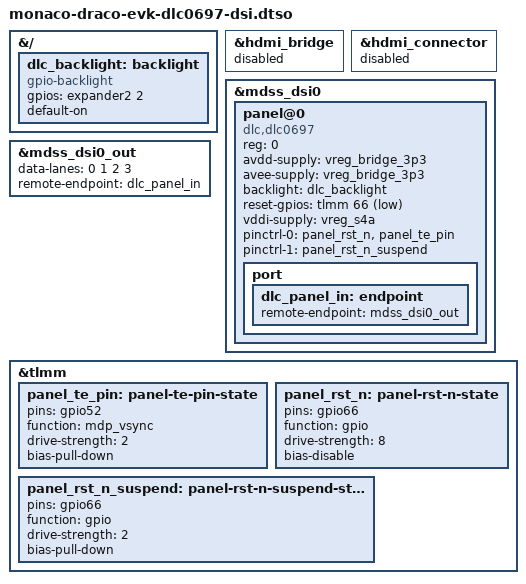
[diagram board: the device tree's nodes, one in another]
// SPDX-License-Identifier: BSD-3-Clause
/*
 * Copyright (c) Qualcomm Technologies, Inc. and/or its subsidiaries.
 */

/dts-v1/;
/plugin/;

#include <dt-bindings/gpio/gpio.h>

&{/} {
	dlc_backlight: backlight {
		compatible = "gpio-backlight";
		gpios = <&expander2 2 GPIO_ACTIVE_HIGH>;
		default-on;
	};
};

&hdmi_bridge {
	status = "disabled";
};

&hdmi_connector {
	status = "disabled";
};

&mdss_dsi0 {
	#address-cells = <1>;
	#size-cells = <0>;

	panel@0 {
		compatible = "dlc,dlc0697", "ilitek,ili7807s";
		reg = <0>;

		avdd-supply = <&vreg_bridge_3p3>;
		avee-supply = <&vreg_bridge_3p3>;
		backlight = <&dlc_backlight>;
		reset-gpios = <&tlmm 66 GPIO_ACTIVE_LOW>;
		vddi-supply = <&vreg_s4a>;

		pinctrl-0 = <&panel_rst_n &panel_te_pin>;
		pinctrl-1 = <&panel_rst_n_suspend>;
		pinctrl-names = "default", "sleep";

		port {
			dlc_panel_in: endpoint {
				remote-endpoint = <&mdss_dsi0_out>;
			};
		};
	};
};

&mdss_dsi0_out {
	data-lanes = <0 1 2 3>;
	remote-endpoint = <&dlc_panel_in>;
};

&tlmm {
	panel_te_pin: panel-te-pin-state {
		pins = "gpio52";
		function = "mdp_vsync";
		drive-strength = <2>;
		bias-pull-down;
	};

	panel_rst_n: panel-rst-n-state {
		pins = "gpio66";
		function = "gpio";
		drive-strength = <8>;
		bias-disable;
	};

	panel_rst_n_suspend: panel-rst-n-suspend-state {
		pins = "gpio66";
		function = "gpio";
		drive-strength = <2>;
		bias-pull-down;
	};
};
